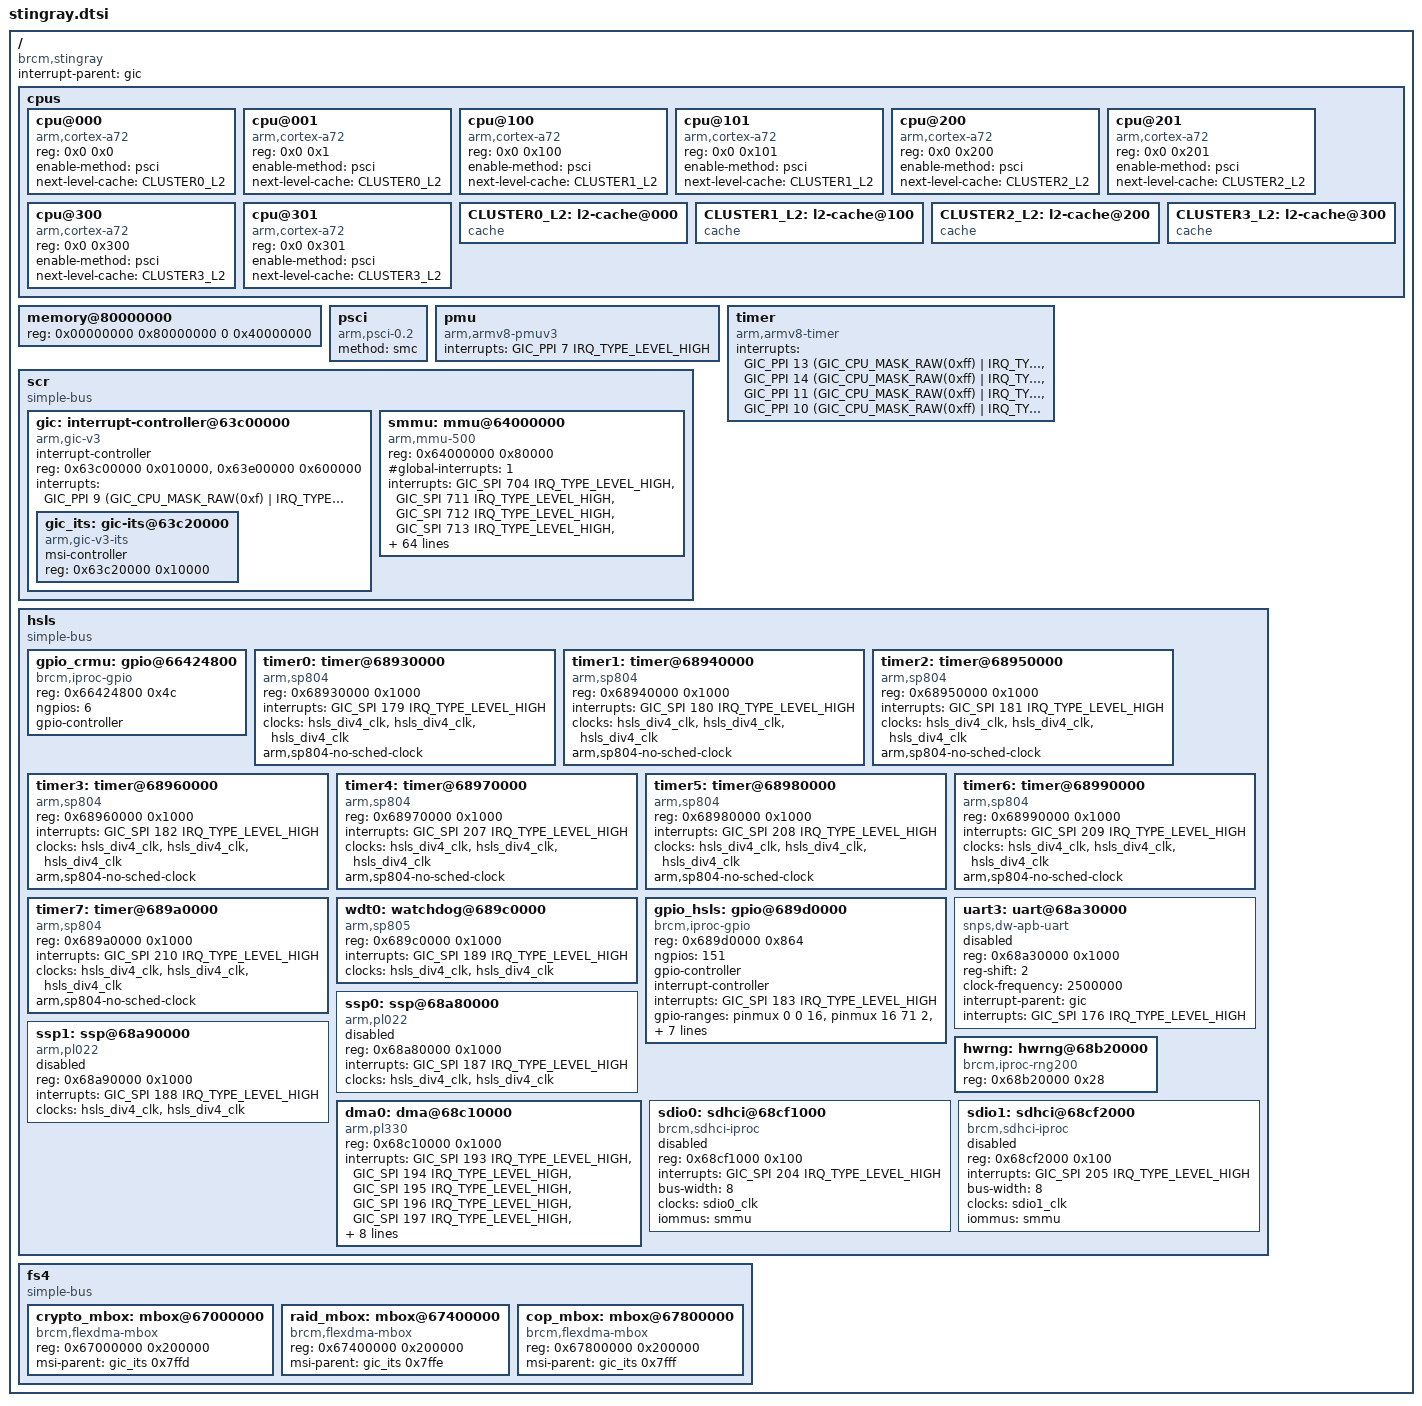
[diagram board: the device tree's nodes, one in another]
/*
 *  BSD LICENSE
 *
 *  Copyright(c) 2015 Broadcom Corporation.  All rights reserved.
 *
 *  Redistribution and use in source and binary forms, with or without
 *  modification, are permitted provided that the following conditions
 *  are met:
 *
 *    * Redistributions of source code must retain the above copyright
 *      notice, this list of conditions and the following disclaimer.
 *    * Redistributions in binary form must reproduce the above copyright
 *      notice, this list of conditions and the following disclaimer in
 *      the documentation and/or other materials provided with the
 *      distribution.
 *    * Neither the name of Broadcom Corporation nor the names of its
 *      contributors may be used to endorse or promote products derived
 *      from this software without specific prior written permission.
 *
 *  THIS SOFTWARE IS PROVIDED BY THE COPYRIGHT HOLDERS AND CONTRIBUTORS
 *  "AS IS" AND ANY EXPRESS OR IMPLIED WARRANTIES, INCLUDING, BUT NOT
 *  LIMITED TO, THE IMPLIED WARRANTIES OF MERCHANTABILITY AND FITNESS FOR
 *  A PARTICULAR PURPOSE ARE DISCLAIMED. IN NO EVENT SHALL THE COPYRIGHT
 *  OWNER OR CONTRIBUTORS BE LIABLE FOR ANY DIRECT, INDIRECT, INCIDENTAL,
 *  SPECIAL, EXEMPLARY, OR CONSEQUENTIAL DAMAGES (INCLUDING, BUT NOT
 *  LIMITED TO, PROCUREMENT OF SUBSTITUTE GOODS OR SERVICES; LOSS OF USE,
 *  DATA, OR PROFITS; OR BUSINESS INTERRUPTION) HOWEVER CAUSED AND ON ANY
 *  THEORY OF LIABILITY, WHETHER IN CONTRACT, STRICT LIABILITY, OR TORT
 *  (INCLUDING NEGLIGENCE OR OTHERWISE) ARISING IN ANY WAY OUT OF THE USE
 * OF THIS SOFTWARE, EVEN IF ADVISED OF THE POSSIBILITY OF SUCH DAMAGE.
 */

#include <dt-bindings/interrupt-controller/arm-gic.h>
#include <dt-bindings/pinctrl/brcm,pinctrl-stingray.h>

/ {
	compatible = "brcm,stingray";
	interrupt-parent = <&gic>;
	#address-cells = <2>;
	#size-cells = <2>;

	cpus {
		#address-cells = <2>;
		#size-cells = <0>;

		cpu@000 {
			device_type = "cpu";
			compatible = "arm,cortex-a72", "arm,armv8";
			reg = <0x0 0x0>;
			enable-method = "psci";
			next-level-cache = <&CLUSTER0_L2>;
		};

		cpu@001 {
			device_type = "cpu";
			compatible = "arm,cortex-a72", "arm,armv8";
			reg = <0x0 0x1>;
			enable-method = "psci";
			next-level-cache = <&CLUSTER0_L2>;
		};

		cpu@100 {
			device_type = "cpu";
			compatible = "arm,cortex-a72", "arm,armv8";
			reg = <0x0 0x100>;
			enable-method = "psci";
			next-level-cache = <&CLUSTER1_L2>;
		};

		cpu@101 {
			device_type = "cpu";
			compatible = "arm,cortex-a72", "arm,armv8";
			reg = <0x0 0x101>;
			enable-method = "psci";
			next-level-cache = <&CLUSTER1_L2>;
		};

		cpu@200 {
			device_type = "cpu";
			compatible = "arm,cortex-a72", "arm,armv8";
			reg = <0x0 0x200>;
			enable-method = "psci";
			next-level-cache = <&CLUSTER2_L2>;
		};

		cpu@201 {
			device_type = "cpu";
			compatible = "arm,cortex-a72", "arm,armv8";
			reg = <0x0 0x201>;
			enable-method = "psci";
			next-level-cache = <&CLUSTER2_L2>;
		};

		cpu@300 {
			device_type = "cpu";
			compatible = "arm,cortex-a72", "arm,armv8";
			reg = <0x0 0x300>;
			enable-method = "psci";
			next-level-cache = <&CLUSTER3_L2>;
		};

		cpu@301 {
			device_type = "cpu";
			compatible = "arm,cortex-a72", "arm,armv8";
			reg = <0x0 0x301>;
			enable-method = "psci";
			next-level-cache = <&CLUSTER3_L2>;
		};

		CLUSTER0_L2: l2-cache@000 {
			compatible = "cache";
		};

		CLUSTER1_L2: l2-cache@100 {
			compatible = "cache";
		};

		CLUSTER2_L2: l2-cache@200 {
			compatible = "cache";
		};

		CLUSTER3_L2: l2-cache@300 {
			compatible = "cache";
		};
	};

	memory@80000000 {
		device_type = "memory";
		reg = <0x00000000 0x80000000 0 0x40000000>;
	};

	psci {
		compatible = "arm,psci-0.2";
		method = "smc";
	};

	pmu {
		compatible = "arm,armv8-pmuv3";
		interrupts = <GIC_PPI 7 IRQ_TYPE_LEVEL_HIGH>;
	};

	timer {
		compatible = "arm,armv8-timer";
		interrupts = <GIC_PPI 13 (GIC_CPU_MASK_RAW(0xff) |
			      IRQ_TYPE_EDGE_RISING)>,
			     <GIC_PPI 14 (GIC_CPU_MASK_RAW(0xff) |
			      IRQ_TYPE_EDGE_RISING)>,
			     <GIC_PPI 11 (GIC_CPU_MASK_RAW(0xff) |
			      IRQ_TYPE_EDGE_RISING)>,
			     <GIC_PPI 10 (GIC_CPU_MASK_RAW(0xff) |
			      IRQ_TYPE_EDGE_RISING)>;
	};

	scr {
		compatible = "simple-bus";
		#address-cells = <1>;
		#size-cells = <1>;
		ranges = <0 0 0 0xffffffff>;

		gic: interrupt-controller@63c00000 {
			compatible = "arm,gic-v3";
			#interrupt-cells = <3>;
			#address-cells = <1>;
			#size-cells = <1>;
			ranges;
			interrupt-controller;
			reg = <0x63c00000 0x010000>, /* GICD */
			      <0x63e00000 0x600000>; /* GICR */
			interrupts = <GIC_PPI 9 (GIC_CPU_MASK_RAW(0xf) |
				      IRQ_TYPE_LEVEL_HIGH)>;

			gic_its: gic-its@63c20000 {
				compatible = "arm,gic-v3-its";
				msi-controller;
				#msi-cells = <1>;
				reg = <0x63c20000 0x10000>;
			};
		};

		smmu: mmu@64000000 {
			compatible = "arm,mmu-500";
			reg = <0x64000000 0x80000>;
			#global-interrupts = <1>;
			interrupts = <GIC_SPI 704 IRQ_TYPE_LEVEL_HIGH>,
				     <GIC_SPI 711 IRQ_TYPE_LEVEL_HIGH>,
				     <GIC_SPI 712 IRQ_TYPE_LEVEL_HIGH>,
				     <GIC_SPI 713 IRQ_TYPE_LEVEL_HIGH>,
				     <GIC_SPI 714 IRQ_TYPE_LEVEL_HIGH>,
				     <GIC_SPI 715 IRQ_TYPE_LEVEL_HIGH>,
				     <GIC_SPI 716 IRQ_TYPE_LEVEL_HIGH>,
				     <GIC_SPI 717 IRQ_TYPE_LEVEL_HIGH>,
				     <GIC_SPI 718 IRQ_TYPE_LEVEL_HIGH>,
				     <GIC_SPI 719 IRQ_TYPE_LEVEL_HIGH>,
				     <GIC_SPI 720 IRQ_TYPE_LEVEL_HIGH>,
				     <GIC_SPI 721 IRQ_TYPE_LEVEL_HIGH>,
				     <GIC_SPI 722 IRQ_TYPE_LEVEL_HIGH>,
				     <GIC_SPI 723 IRQ_TYPE_LEVEL_HIGH>,
				     <GIC_SPI 724 IRQ_TYPE_LEVEL_HIGH>,
				     <GIC_SPI 725 IRQ_TYPE_LEVEL_HIGH>,
				     <GIC_SPI 726 IRQ_TYPE_LEVEL_HIGH>,
				     <GIC_SPI 727 IRQ_TYPE_LEVEL_HIGH>,
				     <GIC_SPI 728 IRQ_TYPE_LEVEL_HIGH>,
				     <GIC_SPI 729 IRQ_TYPE_LEVEL_HIGH>,
				     <GIC_SPI 730 IRQ_TYPE_LEVEL_HIGH>,
				     <GIC_SPI 731 IRQ_TYPE_LEVEL_HIGH>,
				     <GIC_SPI 732 IRQ_TYPE_LEVEL_HIGH>,
				     <GIC_SPI 733 IRQ_TYPE_LEVEL_HIGH>,
				     <GIC_SPI 734 IRQ_TYPE_LEVEL_HIGH>,
				     <GIC_SPI 735 IRQ_TYPE_LEVEL_HIGH>,
				     <GIC_SPI 736 IRQ_TYPE_LEVEL_HIGH>,
				     <GIC_SPI 737 IRQ_TYPE_LEVEL_HIGH>,
				     <GIC_SPI 738 IRQ_TYPE_LEVEL_HIGH>,
				     <GIC_SPI 739 IRQ_TYPE_LEVEL_HIGH>,
				     <GIC_SPI 740 IRQ_TYPE_LEVEL_HIGH>,
				     <GIC_SPI 741 IRQ_TYPE_LEVEL_HIGH>,
				     <GIC_SPI 742 IRQ_TYPE_LEVEL_HIGH>,
				     <GIC_SPI 743 IRQ_TYPE_LEVEL_HIGH>,
				     <GIC_SPI 744 IRQ_TYPE_LEVEL_HIGH>,
				     <GIC_SPI 745 IRQ_TYPE_LEVEL_HIGH>,
				     <GIC_SPI 746 IRQ_TYPE_LEVEL_HIGH>,
				     <GIC_SPI 747 IRQ_TYPE_LEVEL_HIGH>,
				     <GIC_SPI 748 IRQ_TYPE_LEVEL_HIGH>,
				     <GIC_SPI 749 IRQ_TYPE_LEVEL_HIGH>,
				     <GIC_SPI 750 IRQ_TYPE_LEVEL_HIGH>,
				     <GIC_SPI 751 IRQ_TYPE_LEVEL_HIGH>,
				     <GIC_SPI 752 IRQ_TYPE_LEVEL_HIGH>,
				     <GIC_SPI 753 IRQ_TYPE_LEVEL_HIGH>,
				     <GIC_SPI 754 IRQ_TYPE_LEVEL_HIGH>,
				     <GIC_SPI 755 IRQ_TYPE_LEVEL_HIGH>,
				     <GIC_SPI 756 IRQ_TYPE_LEVEL_HIGH>,
				     <GIC_SPI 757 IRQ_TYPE_LEVEL_HIGH>,
				     <GIC_SPI 758 IRQ_TYPE_LEVEL_HIGH>,
				     <GIC_SPI 759 IRQ_TYPE_LEVEL_HIGH>,
				     <GIC_SPI 760 IRQ_TYPE_LEVEL_HIGH>,
				     <GIC_SPI 761 IRQ_TYPE_LEVEL_HIGH>,
				     <GIC_SPI 762 IRQ_TYPE_LEVEL_HIGH>,
				     <GIC_SPI 763 IRQ_TYPE_LEVEL_HIGH>,
				     <GIC_SPI 764 IRQ_TYPE_LEVEL_HIGH>,
				     <GIC_SPI 765 IRQ_TYPE_LEVEL_HIGH>,
				     <GIC_SPI 766 IRQ_TYPE_LEVEL_HIGH>,
				     <GIC_SPI 767 IRQ_TYPE_LEVEL_HIGH>,
				     <GIC_SPI 768 IRQ_TYPE_LEVEL_HIGH>,
				     <GIC_SPI 769 IRQ_TYPE_LEVEL_HIGH>,
				     <GIC_SPI 770 IRQ_TYPE_LEVEL_HIGH>,
				     <GIC_SPI 771 IRQ_TYPE_LEVEL_HIGH>,
				     <GIC_SPI 772 IRQ_TYPE_LEVEL_HIGH>,
				     <GIC_SPI 773 IRQ_TYPE_LEVEL_HIGH>,
				     <GIC_SPI 774 IRQ_TYPE_LEVEL_HIGH>;
			mmu-masters = <&dma0 0x6000>,
				      <&sdio0 0x6002>,
				      <&sdio1 0x6003>;
			smmu-inst-as-data;
			#iommu-cells = <0>;
		};
	};

	hsls {
		compatible = "simple-bus";
		#address-cells = <1>;
		#size-cells = <1>;
		ranges = <0 0 0 0xffffffff>;

		#include "stingray-clock.dtsi"
		#include "stingray-pinctrl.dtsi"

		gpio_crmu: gpio@66424800 {
			compatible = "brcm,iproc-gpio";
			reg = <0x66424800 0x4c>;
			ngpios = <6>;
			#gpio-cells = <2>;
			gpio-controller;
		};

		timer0: timer@68930000 {
			compatible = "arm,sp804", "arm,primecell";
			reg = <0x68930000 0x1000>;
			interrupts = <GIC_SPI 179 IRQ_TYPE_LEVEL_HIGH>;
			clocks = <&hsls_div4_clk>,
				 <&hsls_div4_clk>,
				 <&hsls_div4_clk>;
			clock-names = "timer1", "timer2", "apb_pclk";
			arm,sp804-no-sched-clock;
		};

		timer1: timer@68940000 {
			compatible = "arm,sp804", "arm,primecell";
			reg = <0x68940000 0x1000>;
			interrupts = <GIC_SPI 180 IRQ_TYPE_LEVEL_HIGH>;
			clocks = <&hsls_div4_clk>,
				 <&hsls_div4_clk>,
				 <&hsls_div4_clk>;
			clock-names = "timer1", "timer2", "apb_pclk";
			arm,sp804-no-sched-clock;
		};

		timer2: timer@68950000 {
			compatible = "arm,sp804", "arm,primecell";
			reg = <0x68950000 0x1000>;
			interrupts = <GIC_SPI 181 IRQ_TYPE_LEVEL_HIGH>;
			clocks = <&hsls_div4_clk>,
				 <&hsls_div4_clk>,
				 <&hsls_div4_clk>;
			clock-names = "timer1", "timer2", "apb_pclk";
			arm,sp804-no-sched-clock;
		};

		timer3: timer@68960000 {
			compatible = "arm,sp804", "arm,primecell";
			reg = <0x68960000 0x1000>;
			interrupts = <GIC_SPI 182 IRQ_TYPE_LEVEL_HIGH>;
			clocks = <&hsls_div4_clk>,
				 <&hsls_div4_clk>,
				 <&hsls_div4_clk>;
			clock-names = "timer1", "timer2", "apb_pclk";
			arm,sp804-no-sched-clock;
		};

		timer4: timer@68970000 {
			compatible = "arm,sp804", "arm,primecell";
			reg = <0x68970000 0x1000>;
			interrupts = <GIC_SPI 207 IRQ_TYPE_LEVEL_HIGH>;
			clocks = <&hsls_div4_clk>,
				 <&hsls_div4_clk>,
				 <&hsls_div4_clk>;
			clock-names = "timer1", "timer2", "apb_pclk";
			arm,sp804-no-sched-clock;
		};

		timer5: timer@68980000 {
			compatible = "arm,sp804", "arm,primecell";
			reg = <0x68980000 0x1000>;
			interrupts = <GIC_SPI 208 IRQ_TYPE_LEVEL_HIGH>;
			clocks = <&hsls_div4_clk>,
				 <&hsls_div4_clk>,
				 <&hsls_div4_clk>;
			clock-names = "timer1", "timer2", "apb_pclk";
			arm,sp804-no-sched-clock;
		};

		timer6: timer@68990000 {
			compatible = "arm,sp804", "arm,primecell";
			reg = <0x68990000 0x1000>;
			interrupts = <GIC_SPI 209 IRQ_TYPE_LEVEL_HIGH>;
			clocks = <&hsls_div4_clk>,
				 <&hsls_div4_clk>,
				 <&hsls_div4_clk>;
			clock-names = "timer1", "timer2", "apb_pclk";
			arm,sp804-no-sched-clock;
		};

		timer7: timer@689a0000 {
			compatible = "arm,sp804", "arm,primecell";
			reg = <0x689a0000 0x1000>;
			interrupts = <GIC_SPI 210 IRQ_TYPE_LEVEL_HIGH>;
			clocks = <&hsls_div4_clk>,
				 <&hsls_div4_clk>,
				 <&hsls_div4_clk>;
			clock-names = "timer1", "timer2", "apb_pclk";
			arm,sp804-no-sched-clock;
		};

		wdt0: watchdog@689c0000 {
			compatible = "arm,sp805", "arm,primecell";
			reg = <0x689c0000 0x1000>;
			interrupts = <GIC_SPI 189 IRQ_TYPE_LEVEL_HIGH>;
			clocks = <&hsls_div4_clk>, <&hsls_div4_clk>;
			clock-names = "wdogclk", "apb_pclk";
		};

		gpio_hsls: gpio@689d0000 {
			compatible = "brcm,iproc-gpio";
			reg = <0x689d0000 0x864>;
			ngpios = <151>;
			#gpio-cells = <2>;
			gpio-controller;
			interrupt-controller;
			interrupts = <GIC_SPI 183 IRQ_TYPE_LEVEL_HIGH>;
			gpio-ranges = <&pinmux 0 0 16>,
					<&pinmux 16 71 2>,
					<&pinmux 18 131 8>,
					<&pinmux 26 83 6>,
					<&pinmux 32 123 4>,
					<&pinmux 36 43 24>,
					<&pinmux 60 89 2>,
					<&pinmux 62 73 4>,
					<&pinmux 66 95 28>,
					<&pinmux 94 127 4>,
					<&pinmux 98 139 10>,
					<&pinmux 108 16 27>,
					<&pinmux 135 77 6>,
					<&pinmux 141 67 4>,
					<&pinmux 145 149 6>,
					<&pinmux 151 91 4>;
		};

		uart3: uart@68a30000 {
			device_type = "serial";
			compatible = "snps,dw-apb-uart";
			reg = <0x68a30000 0x1000>;
			reg-shift = <2>;
			clock-frequency = <2500000>;
			interrupt-parent = <&gic>;
			interrupts = <GIC_SPI 176 IRQ_TYPE_LEVEL_HIGH>;
			status = "disabled";
		};

		ssp0: ssp@68a80000 {
			compatible = "arm,pl022", "arm,primecell";
			reg = <0x68a80000 0x1000>;
			interrupts = <GIC_SPI 187 IRQ_TYPE_LEVEL_HIGH>;
			clocks = <&hsls_div4_clk>, <&hsls_div4_clk>;
			clock-names = "spiclk", "apb_pclk";
			#address-cells = <1>;
			#size-cells = <0>;
			status = "disabled";
		};

		ssp1: ssp@68a90000 {
			compatible = "arm,pl022", "arm,primecell";
			reg = <0x68a90000 0x1000>;
			interrupts = <GIC_SPI 188 IRQ_TYPE_LEVEL_HIGH>;
			clocks = <&hsls_div4_clk>, <&hsls_div4_clk>;
			clock-names = "spiclk", "apb_pclk";
			#address-cells = <1>;
			#size-cells = <0>;
			status = "disabled";
		};

		hwrng: hwrng@68b20000 {
			compatible = "brcm,iproc-rng200";
			reg = <0x68b20000 0x28>;
		};

		dma0: dma@68c10000 {
			compatible = "arm,pl330", "arm,primecell";
			reg = <0x68c10000 0x1000>;
			interrupts = <GIC_SPI 193 IRQ_TYPE_LEVEL_HIGH>,
				     <GIC_SPI 194 IRQ_TYPE_LEVEL_HIGH>,
				     <GIC_SPI 195 IRQ_TYPE_LEVEL_HIGH>,
				     <GIC_SPI 196 IRQ_TYPE_LEVEL_HIGH>,
				     <GIC_SPI 197 IRQ_TYPE_LEVEL_HIGH>,
				     <GIC_SPI 198 IRQ_TYPE_LEVEL_HIGH>,
				     <GIC_SPI 199 IRQ_TYPE_LEVEL_HIGH>,
				     <GIC_SPI 200 IRQ_TYPE_LEVEL_HIGH>,
				     <GIC_SPI 201 IRQ_TYPE_LEVEL_HIGH>;
			#dma-cells = <1>;
			#dma-channels = <8>;
			#dma-requests = <32>;
			clocks = <&hsls_div2_clk>;
			clock-names = "apb_pclk";
			#stream-id-cells = <1>;
			iommus = <&smmu>;
		};

		sdio0: sdhci@68cf1000 {
			compatible = "brcm,sdhci-iproc";
			reg = <0x68cf1000 0x100>;
			interrupts = <GIC_SPI 204 IRQ_TYPE_LEVEL_HIGH>;
			bus-width = <8>;
			clocks = <&sdio0_clk>;
			#stream-id-cells = <1>;
			iommus = <&smmu>;
			status = "disabled";
		};

		sdio1: sdhci@68cf2000 {
			compatible = "brcm,sdhci-iproc";
			reg = <0x68cf2000 0x100>;
			interrupts = <GIC_SPI 205 IRQ_TYPE_LEVEL_HIGH>;
			bus-width = <8>;
			clocks = <&sdio1_clk>;
			#stream-id-cells = <1>;
			iommus = <&smmu>;
			status = "disabled";
		};
	};

	fs4 {
		compatible = "simple-bus";
		#address-cells = <1>;
		#size-cells = <1>;
		ranges = <0 0 0 0xffffffff>;

		crypto_mbox: mbox@67000000 {
			compatible = "brcm,flexdma-mbox";
			reg = <0x67000000 0x200000>;
			msi-parent = <&gic_its 0x7ffd>;
			#mbox-cells = <3>;
		};

		raid_mbox: mbox@67400000 {
			compatible = "brcm,flexdma-mbox";
			reg = <0x67400000 0x200000>;
			msi-parent = <&gic_its 0x7ffe>;
			#mbox-cells = <3>;
		};

		cop_mbox: mbox@67800000 {
			compatible = "brcm,flexdma-mbox";
			reg = <0x67800000 0x200000>;
			msi-parent = <&gic_its 0x7fff>;
			#mbox-cells = <3>;
		};
	};
};
